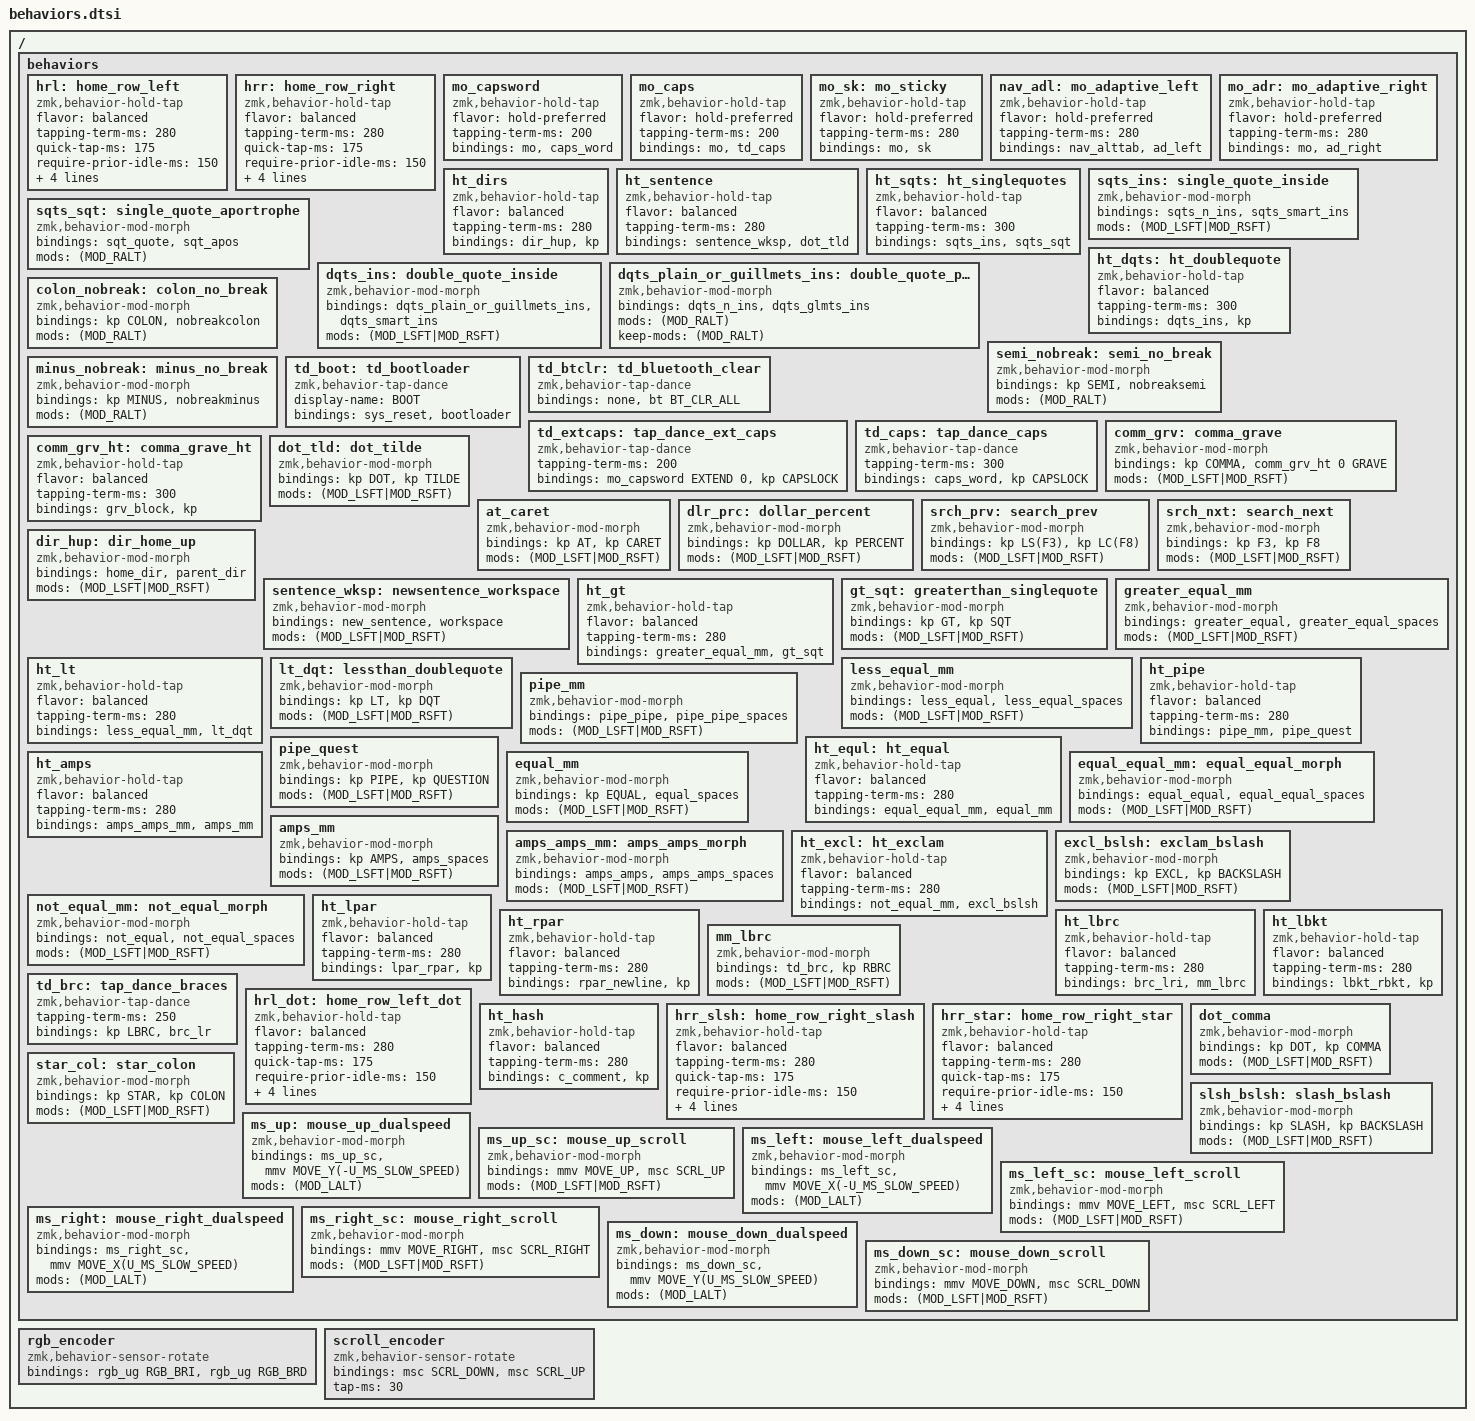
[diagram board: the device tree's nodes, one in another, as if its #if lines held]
/* Behaviors */

/ {

    behaviors {
        hrl: home_row_left {
            compatible = "zmk,behavior-hold-tap";
            #binding-cells = <2>;
            flavor = "balanced";
            tapping-term-ms = <280>;
            quick-tap-ms = <175>;
            require-prior-idle-ms = <150>;
            bindings = <&kp>, <&kp>;
            hold-trigger-key-positions = <KEYS_RIGHT KEYS_THUMBS KEYS_5WAY>;
            hold-trigger-on-release;             // delay positional check until key-release
        };

        hrr: home_row_right {
            compatible = "zmk,behavior-hold-tap";
            #binding-cells = <2>;
            flavor = "balanced";
            tapping-term-ms = <280>;
            quick-tap-ms = <175>;
            require-prior-idle-ms = <150>;
            bindings = <&kp>, <&kp>;
            hold-trigger-key-positions = <KEYS_LEFT KEYS_THUMBS KEY_ENCODER>;
            hold-trigger-on-release;             // delay positional check until key-release
        };

        mo_capsword: mo_capsword {
            compatible = "zmk,behavior-hold-tap";
            #binding-cells = <2>;
            flavor = "hold-preferred";
            tapping-term-ms = <200>;
            bindings = <&mo>, <&caps_word>;
        };

        mo_caps: mo_caps {
            compatible = "zmk,behavior-hold-tap";
            #binding-cells = <2>;
            flavor = "hold-preferred";
            tapping-term-ms = <200>;
            bindings = <&mo>, <&td_caps>;
        };

        mo_sk: mo_sticky {
            compatible = "zmk,behavior-hold-tap";
            #binding-cells = <2>;
            flavor = "hold-preferred";
            tapping-term-ms = <280>;
            bindings = <&mo>, <&sk>;
        };

        nav_adl: mo_adaptive_left {
            compatible = "zmk,behavior-hold-tap";
            #binding-cells = <2>;
            flavor = "hold-preferred";
            tapping-term-ms = <280>;
            bindings = <&nav_alttab>, <&ad_left>;
        };
        mo_adr: mo_adaptive_right {
            compatible = "zmk,behavior-hold-tap";
            #binding-cells = <2>;
            flavor = "hold-preferred";
            tapping-term-ms = <280>;
            bindings = <&mo>, <&ad_right>;
        };

        ht_dirs: ht_dirs {
            compatible = "zmk,behavior-hold-tap";
            #binding-cells = <2>;
            flavor = "balanced";
            tapping-term-ms = <280>;
            bindings = <&dir_hup>, <&kp>;
        };

        ht_sentence: ht_sentence {
            compatible = "zmk,behavior-hold-tap";
            #binding-cells = <2>;
            flavor = "balanced";
            tapping-term-ms = <280>;
            bindings = <&sentence_wksp>, <&dot_tld>;
        };

        ht_sqts: ht_singlequotes {
            compatible = "zmk,behavior-hold-tap";
            #binding-cells = <2>;
            flavor = "balanced";
            tapping-term-ms = <300>;
            bindings = <&sqts_ins>, <&sqts_sqt>;
        };
        sqts_ins: single_quote_inside {
            compatible = "zmk,behavior-mod-morph";
            #binding-cells = <0>;
            bindings = <&sqts_n_ins>, <&sqts_smart_ins>;
            mods = <(MOD_LSFT|MOD_RSFT)>;
        };
        sqts_sqt: single_quote_aportrophe {
            compatible = "zmk,behavior-mod-morph";
            #binding-cells = <0>;
            bindings = <&sqt_quote>, <&sqt_apos>;
            mods = <(MOD_RALT)>;
        };
        ht_dqts: ht_doublequote {
            compatible = "zmk,behavior-hold-tap";
            #binding-cells = <2>;
            flavor = "balanced";
            tapping-term-ms = <300>;
            bindings = <&dqts_ins>, <&kp>;
        };
        dqts_ins: double_quote_inside {
            compatible = "zmk,behavior-mod-morph";
            #binding-cells = <0>;
            bindings = <&dqts_plain_or_guillmets_ins>, <&dqts_smart_ins>;
            mods = <(MOD_LSFT|MOD_RSFT)>;
        };
        dqts_plain_or_guillmets_ins: double_quote_plain_or_guillemets_inside {
            compatible = "zmk,behavior-mod-morph";
            #binding-cells = <0>;
            bindings = <&dqts_n_ins>, <&dqts_glmts_ins>;
            mods = <(MOD_RALT)>;
            keep-mods = <(MOD_RALT)>;
        };
        colon_nobreak: colon_no_break {
            compatible = "zmk,behavior-mod-morph";
            #binding-cells = <0>;
            bindings = <&kp COLON>, <&nobreakcolon>;
            mods = <(MOD_RALT)>;
        };
        semi_nobreak: semi_no_break {
            compatible = "zmk,behavior-mod-morph";
            #binding-cells = <0>;
            bindings = <&kp SEMI>, <&nobreaksemi>;
            mods = <(MOD_RALT)>;
        };
        minus_nobreak: minus_no_break {
            compatible = "zmk,behavior-mod-morph";
            #binding-cells = <0>;
            bindings = <&kp MINUS>, <&nobreakminus>;
            mods = <(MOD_RALT)>;
        };

        td_boot: td_bootloader {
            compatible = "zmk,behavior-tap-dance";
            display-name = "BOOT";
            #binding-cells = <0>;
            bindings = <&sys_reset>, <&bootloader>;
        };

        td_btclr: td_bluetooth_clear {
            compatible = "zmk,behavior-tap-dance";
            #binding-cells = <0>;
            bindings = <&none>, <&bt BT_CLR_ALL>;
        };

        td_extcaps: tap_dance_ext_caps {
            compatible = "zmk,behavior-tap-dance";
            #binding-cells = <0>;
            tapping-term-ms = <200>;
            bindings = <&mo_capsword EXTEND 0>, <&kp CAPSLOCK>;
        };

        td_caps: tap_dance_caps {
            compatible = "zmk,behavior-tap-dance";
            #binding-cells = <0>;
            tapping-term-ms = <300>;
            bindings = <&caps_word>, <&kp CAPSLOCK>;
        };

        comm_grv: comma_grave {
            compatible = "zmk,behavior-mod-morph";
            #binding-cells = <0>;
            bindings = <&kp COMMA>, <&comm_grv_ht 0 GRAVE>;
            mods = <(MOD_LSFT|MOD_RSFT)>;
        };
        comm_grv_ht: comma_grave_ht {
            compatible = "zmk,behavior-hold-tap";
            #binding-cells = <2>;
            flavor = "balanced";
            tapping-term-ms = <300>;
            bindings = <&grv_block>, <&kp>;
        };

        dot_tld: dot_tilde {
            compatible = "zmk,behavior-mod-morph";
            #binding-cells = <0>;
            bindings = <&kp DOT>, <&kp TILDE>;
            mods = <(MOD_LSFT|MOD_RSFT)>;
        };
        at_caret: at_caret {
            compatible = "zmk,behavior-mod-morph";
            #binding-cells = <0>;
            bindings = <&kp AT>, <&kp CARET>;
            mods = <(MOD_LSFT|MOD_RSFT)>;
        };
        dlr_prc: dollar_percent {
            compatible = "zmk,behavior-mod-morph";
            #binding-cells = <0>;
            bindings = <&kp DOLLAR>, <&kp PERCENT>;
            mods = <(MOD_LSFT|MOD_RSFT)>;
        };
        srch_prv: search_prev {
            compatible = "zmk,behavior-mod-morph";
            #binding-cells = <0>;
            bindings = <&kp LS(F3)>, <&kp LC(F8)>;
            mods = <(MOD_LSFT|MOD_RSFT)>;
        };
        srch_nxt: search_next {
            compatible = "zmk,behavior-mod-morph";
            #binding-cells = <0>;
            bindings = <&kp F3>, <&kp F8>;
            mods = <(MOD_LSFT|MOD_RSFT)>;
        };
        dir_hup: dir_home_up {
            compatible = "zmk,behavior-mod-morph";
            #binding-cells = <0>;
            bindings = <&home_dir>, <&parent_dir>;
            mods = <(MOD_LSFT|MOD_RSFT)>;
        };
        sentence_wksp: newsentence_workspace {
            compatible = "zmk,behavior-mod-morph";
            #binding-cells = <0>;
            bindings = <&new_sentence>, <&workspace>;
            mods = <(MOD_LSFT|MOD_RSFT)>;
        };

        // Symbols mod-morphs and hold-taps
        ht_gt: ht_gt {
            compatible = "zmk,behavior-hold-tap";
            #binding-cells = <2>;
            flavor = "balanced";
            tapping-term-ms = <280>;
            bindings = <&greater_equal_mm>, <&gt_sqt>;
        };
        gt_sqt: greaterthan_singlequote {
            compatible = "zmk,behavior-mod-morph";
            #binding-cells = <0>;
            bindings = <&kp GT>, <&kp SQT>;
            mods = <(MOD_LSFT|MOD_RSFT)>;
        };
        greater_equal_mm: greater_equal_mm {
            compatible = "zmk,behavior-mod-morph";
            #binding-cells = <0>;
            bindings = <&greater_equal>, <&greater_equal_spaces>;
            mods = <(MOD_LSFT|MOD_RSFT)>;
        };
        ht_lt: ht_lt {
            compatible = "zmk,behavior-hold-tap";
            #binding-cells = <2>;
            flavor = "balanced";
            tapping-term-ms = <280>;
            bindings = <&less_equal_mm>, <&lt_dqt>;
        };
        lt_dqt: lessthan_doublequote {
            compatible = "zmk,behavior-mod-morph";
            #binding-cells = <0>;
            bindings = <&kp LT>, <&kp DQT>;
            mods = <(MOD_LSFT|MOD_RSFT)>;
        };
        less_equal_mm: less_equal_mm {
            compatible = "zmk,behavior-mod-morph";
            #binding-cells = <0>;
            bindings = <&less_equal>, <&less_equal_spaces>;
            mods = <(MOD_LSFT|MOD_RSFT)>;
        };
        ht_pipe: ht_pipe {
            compatible = "zmk,behavior-hold-tap";
            #binding-cells = <2>;
            flavor = "balanced";
            tapping-term-ms = <280>;
            bindings = <&pipe_mm>, <&pipe_quest>;
        };
        pipe_mm: pipe_mm {
            compatible = "zmk,behavior-mod-morph";
            #binding-cells = <0>;
            bindings = <&pipe_pipe>, <&pipe_pipe_spaces>;
            mods = <(MOD_LSFT|MOD_RSFT)>;
        };
        pipe_quest: pipe_quest {
            compatible = "zmk,behavior-mod-morph";
            #binding-cells = <0>;
            bindings = <&kp PIPE>, <&kp QUESTION>;
            mods = <(MOD_LSFT|MOD_RSFT)>;
        };
        ht_equl: ht_equal {
            compatible = "zmk,behavior-hold-tap";
            #binding-cells = <2>;
            flavor = "balanced";
            tapping-term-ms = <280>;
            bindings = <&equal_equal_mm>, <&equal_mm>;
        };
        equal_mm: equal_mm {
            compatible = "zmk,behavior-mod-morph";
            #binding-cells = <0>;
            bindings = <&kp EQUAL>, <&equal_spaces>;
            mods = <(MOD_LSFT|MOD_RSFT)>;
        };
        equal_equal_mm: equal_equal_morph{
            compatible = "zmk,behavior-mod-morph";
            #binding-cells = <0>;
            bindings = <&equal_equal>, <&equal_equal_spaces>;
            mods = <(MOD_LSFT|MOD_RSFT)>;
        };
        ht_amps: ht_amps {
            compatible = "zmk,behavior-hold-tap";
            #binding-cells = <2>;
            flavor = "balanced";
            tapping-term-ms = <280>;
            bindings = <&amps_amps_mm>, <&amps_mm>;
        };
        amps_mm: amps_mm {
            compatible = "zmk,behavior-mod-morph";
            #binding-cells = <0>;
            bindings = <&kp AMPS>, <&amps_spaces>;
            mods = <(MOD_LSFT|MOD_RSFT)>;
        };
        amps_amps_mm: amps_amps_morph{
            compatible = "zmk,behavior-mod-morph";
            #binding-cells = <0>;
            bindings = <&amps_amps>, <&amps_amps_spaces>;
            mods = <(MOD_LSFT|MOD_RSFT)>;
        };
        ht_excl: ht_exclam {
            compatible = "zmk,behavior-hold-tap";
            #binding-cells = <2>;
            flavor = "balanced";
            tapping-term-ms = <280>;
            bindings = <&not_equal_mm>, <&excl_bslsh>;
        };
        excl_bslsh: exclam_bslash {
            compatible = "zmk,behavior-mod-morph";
            #binding-cells = <0>;
            bindings = <&kp EXCL>, <&kp BACKSLASH>;
            mods = <(MOD_LSFT|MOD_RSFT)>;
        };
        not_equal_mm: not_equal_morph{
            compatible = "zmk,behavior-mod-morph";
            #binding-cells = <0>;
            bindings = <&not_equal>, <&not_equal_spaces>;
            mods = <(MOD_LSFT|MOD_RSFT)>;
        };
        ht_lpar: ht_lpar {
            compatible = "zmk,behavior-hold-tap";
            #binding-cells = <2>;
            flavor = "balanced";
            tapping-term-ms = <280>;
            bindings = <&lpar_rpar>, <&kp>;
        };
        ht_rpar: ht_rpar {
            compatible = "zmk,behavior-hold-tap";
            #binding-cells = <2>;
            flavor = "balanced";
            tapping-term-ms = <280>;
            bindings = <&rpar_newline>, <&kp>;
        };
        ht_lbrc: ht_lbrc {
            compatible = "zmk,behavior-hold-tap";
            #binding-cells = <2>;
            flavor = "balanced";
            tapping-term-ms = <280>;
            bindings = <&brc_lri>, <&mm_lbrc>;
        };
        mm_lbrc: mm_lbrc {
            compatible = "zmk,behavior-mod-morph";
            #binding-cells = <0>;
            bindings = <&td_brc>, <&kp RBRC>;
            mods = <(MOD_LSFT|MOD_RSFT)>;
        };
        td_brc: tap_dance_braces {
            compatible = "zmk,behavior-tap-dance";
            #binding-cells = <0>;
            tapping-term-ms = <250>;
            bindings = <&kp LBRC>, <&brc_lr>;
        };
        ht_lbkt: ht_lbkt {
            compatible = "zmk,behavior-hold-tap";
            #binding-cells = <2>;
            flavor = "balanced";
            tapping-term-ms = <280>;
            bindings = <&lbkt_rbkt>, <&kp>;
        };
        // Mod-morphs on HRM on Symbols
        hrl_dot: home_row_left_dot {
            compatible = "zmk,behavior-hold-tap";
            #binding-cells = <2>;
            flavor = "balanced";
            tapping-term-ms = <280>;
            quick-tap-ms = <175>;
            require-prior-idle-ms = <150>;
            bindings = <&kp>, <&dot_comma>;
            hold-trigger-key-positions = <KEYS_RIGHT KEYS_THUMBS KEYS_5WAY>;
            hold-trigger-on-release;             // delay positional check until key-release
        };
        ht_hash: ht_hash {
            compatible = "zmk,behavior-hold-tap";
            #binding-cells = <2>;
            flavor = "balanced";
            tapping-term-ms = <280>;
            bindings = <&c_comment>, <&kp>;
        };
        hrr_slsh: home_row_right_slash {
            compatible = "zmk,behavior-hold-tap";
            #binding-cells = <2>;
            flavor = "balanced";
            tapping-term-ms = <280>;
            quick-tap-ms = <175>;
            require-prior-idle-ms = <150>;
            bindings = <&kp>, <&slsh_bslsh>;
            hold-trigger-key-positions = <KEYS_LEFT KEYS_THUMBS KEY_ENCODER>;
            hold-trigger-on-release;             // delay positional check until key-release
        };
        hrr_star: home_row_right_star {
            compatible = "zmk,behavior-hold-tap";
            #binding-cells = <2>;
            flavor = "balanced";
            tapping-term-ms = <280>;
            quick-tap-ms = <175>;
            require-prior-idle-ms = <150>;
            bindings = <&kp>, <&star_col>;
            hold-trigger-key-positions = <KEYS_LEFT KEYS_THUMBS KEY_ENCODER>;
            hold-trigger-on-release;             // delay positional check until key-release
        };
        dot_comma: dot_comma {
            compatible = "zmk,behavior-mod-morph";
            #binding-cells = <0>;
            bindings = <&kp DOT>, <&kp COMMA>;
            mods = <(MOD_LSFT|MOD_RSFT)>;
        };
        slsh_bslsh: slash_bslash {
            compatible = "zmk,behavior-mod-morph";
            #binding-cells = <0>;
            bindings = <&kp SLASH>, <&kp BACKSLASH>;
            mods = <(MOD_LSFT|MOD_RSFT)>;
        };
        star_col: star_colon {
            compatible = "zmk,behavior-mod-morph";
            #binding-cells = <0>;
            bindings = <&kp STAR>, <&kp COLON>;
            mods = <(MOD_LSFT|MOD_RSFT)>;
        };

        ms_up: mouse_up_dualspeed {
            compatible = "zmk,behavior-mod-morph";
            #binding-cells = <0>;
            bindings = <&ms_up_sc>, <&mmv MOVE_Y(-U_MS_SLOW_SPEED)>;
            mods = <(MOD_LALT)>;
        };
        ms_up_sc: mouse_up_scroll {
            compatible = "zmk,behavior-mod-morph";
            #binding-cells = <0>;
            bindings = <&mmv MOVE_UP>, <&msc SCRL_UP>;
            mods = <(MOD_LSFT|MOD_RSFT)>;
        };
        ms_left: mouse_left_dualspeed {
            compatible = "zmk,behavior-mod-morph";
            #binding-cells = <0>;
            bindings = <&ms_left_sc>, <&mmv MOVE_X(-U_MS_SLOW_SPEED)>;
            mods = <(MOD_LALT)>;
        };
        ms_left_sc: mouse_left_scroll {
            compatible = "zmk,behavior-mod-morph";
            #binding-cells = <0>;
            bindings = <&mmv MOVE_LEFT>, <&msc SCRL_LEFT>;
            mods = <(MOD_LSFT|MOD_RSFT)>;
        };
        ms_right: mouse_right_dualspeed {
            compatible = "zmk,behavior-mod-morph";
            #binding-cells = <0>;
            bindings = <&ms_right_sc>, <&mmv MOVE_X(U_MS_SLOW_SPEED)>;
            mods = <(MOD_LALT)>;
        };
        ms_right_sc: mouse_right_scroll {
            compatible = "zmk,behavior-mod-morph";
            #binding-cells = <0>;
            bindings = <&mmv MOVE_RIGHT>, <&msc SCRL_RIGHT>;
            mods = <(MOD_LSFT|MOD_RSFT)>;
        };
        ms_down: mouse_down_dualspeed {
            compatible = "zmk,behavior-mod-morph";
            #binding-cells = <0>;
            bindings = <&ms_down_sc>, <&mmv MOVE_Y(U_MS_SLOW_SPEED)>;
            mods = <(MOD_LALT)>;
        };
        ms_down_sc: mouse_down_scroll {
            compatible = "zmk,behavior-mod-morph";
            #binding-cells = <0>;
            bindings = <&mmv MOVE_DOWN>, <&msc SCRL_DOWN>;
            mods = <(MOD_LSFT|MOD_RSFT)>;
        };

    };

#ifdef ENCODERS
    rgb_encoder: rgb_encoder {
        compatible = "zmk,behavior-sensor-rotate";
        #sensor-binding-cells = <0>;
        bindings = <&rgb_ug RGB_BRI>, <&rgb_ug RGB_BRD>;
    };

    scroll_encoder: scroll_encoder {
        compatible = "zmk,behavior-sensor-rotate";
        #sensor-binding-cells = <0>;
        bindings = <&msc SCRL_DOWN>, <&msc SCRL_UP>;
        tap-ms = <30>;
    };
#endif
};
